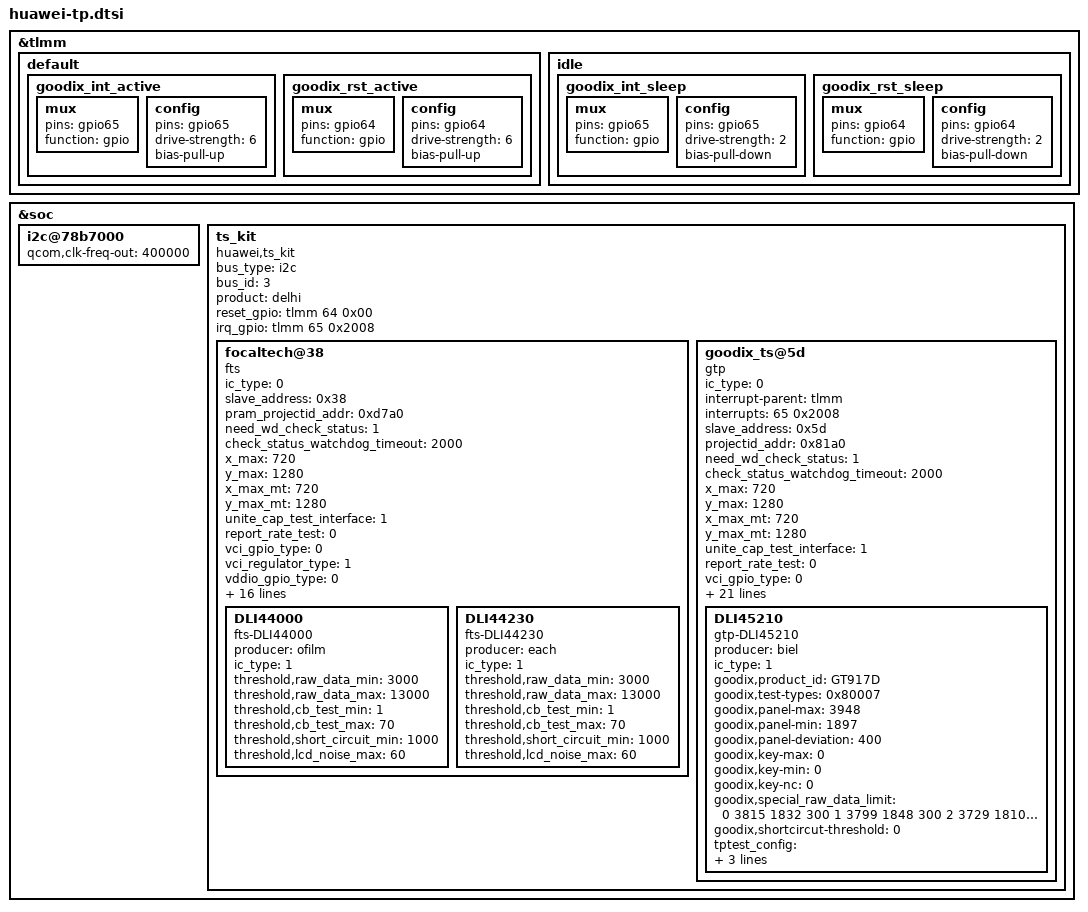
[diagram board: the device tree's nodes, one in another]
/* touch panel config */
&tlmm {

	default {
			goodix_int_active: goodix_int_active{
					mux {
						pins = "gpio65";
						function =  "gpio";
					};
					config {
						pins = "gpio65";
						/*num-grp-pins = <1>;*/
						drive-strength = <6>;
						bias-pull-up;
				};
			};

			goodix_rst_active: goodix_rst_active {
					mux {
						pins = "gpio64";
						function =  "gpio";
					};
					config {
						pins = "gpio64";
						/*num-grp-pins = <1>;*/
						drive-strength = <6>;
						bias-pull-up;
					};
			};
	};

	idle {
			goodix_int_sleep: goodix_int_sleep {
					mux {
						pins = "gpio65";
						function =  "gpio";
					};
					config {
						pins = "gpio65";
						/*num-grp-pins = <1>;*/
						drive-strength = <2>;
						bias-pull-down;
				};
			};

			goodix_rst_sleep: goodix_rst_sleep {
					mux {
						pins = "gpio64";
						function =  "gpio";
					};
					config {
						pins = "gpio64";
						/*num-grp-pins = <1>;*/
						drive-strength = <2>;
						bias-pull-down;
				};
			};
	};

};

&soc {
	i2c@78b7000{
		status = "ok";
		#address-cells = <1>;
		#size-cells = <0>;
		qcom,clk-freq-out = <400000>;
	};
	ts_kit {
		#address-cells = <1>;
		#size-cells = <0>;
		compatible = "huawei,ts_kit";
		bus_type = "i2c";
		bus_id = <3>;
		product = "delhi";
		reset_gpio = <&tlmm 64 0x00>;
		irq_gpio = <&tlmm 65 0x2008>;
		focaltech@38 {
			compatible = "fts";
			ic_type = <0>;
			slave_address = <0x38>;
			pram_projectid_addr = <0xd7a0>;
			need_wd_check_status = <1>;
			check_status_watchdog_timeout = <2000>;
			x_max = <720>;
			y_max = <1280>;
			x_max_mt = <720>;
			y_max_mt = <1280>;
			unite_cap_test_interface =<1>;
			report_rate_test =<0>;
			vci_gpio_type = <0>;
			vci_regulator_type = <1>;
			vddio_gpio_type = <0>;
			vddio_regulator_type = <1>;
			chip_id = <0x54>;
			hard_reset_delay = <200>;
			erase_min_delay = <1350>;
			calc_crc_delay = <300>;
			reboot_delay = <300>;
			erase_query_delay = <50>;
			write_flash_query_times = <30>;
			read_ecc_query_times = <100>;
			erase_flash_query_times = <15>;
			upgrade_loop_times = <5>;
			glove_switch_addr = <0xC0>;
			fts-vdd-supply = <&pm8937_l10>;
			fts-io-supply = <&pm8937_l5>;
			irq_config = <3>;/* 0-low 1-high 2-raising 3-falling */
			algo_id = <1>;
			DLI44000 {
				producer = "ofilm";
				ic_type = <1>;
				compatible = "fts-DLI44000";
				threshold,raw_data_min = <3000>;
				threshold,raw_data_max = <13000>;
				threshold,cb_test_min = <1>;
				threshold,cb_test_max = <70>;
				threshold,short_circuit_min = <1000>;
				//threshold,open_test_cb_min = <100>;
				threshold,lcd_noise_max = <60>;
			};

			DLI44230 {
				producer = "each";
				ic_type = <1>;
				compatible = "fts-DLI44230";
				threshold,raw_data_min = <3000>;
				threshold,raw_data_max = <13000>;
				threshold,cb_test_min = <1>;
				threshold,cb_test_max = <70>;
				threshold,short_circuit_min = <1000>;
				//threshold,open_test_cb_min = <100>;
				threshold,lcd_noise_max = <60>;
			};

		};

		goodix_ts@5d {
			compatible = "gtp";
			ic_type = <0>;
			interrupt-parent = <&tlmm>;
			interrupts = <65 0x2008>;
			slave_address = <0x5d>;
			projectid_addr = <0x81a0>;
			need_wd_check_status = <1>;
			check_status_watchdog_timeout = <2000>;
			x_max = <720>;
			y_max = <1280>;
			x_max_mt = <720>;
			y_max_mt = <1280>;
			unite_cap_test_interface =<1>;
			report_rate_test =<0>;
			vci_gpio_type = <0>;
			vci_regulator_type = <1>;
			vddio_gpio_type = <0>;
			vddio_regulator_type = <1>;
			chip_id = <0x87>;
			hard_reset_delay = <200>;
			erase_min_delay = <1350>;
			calc_crc_delay = <300>;
			reboot_delay = <300>;
			erase_query_delay = <50>;
			write_flash_query_times = <30>;
			read_ecc_query_times = <100>;
			erase_flash_query_times = <15>;
			upgrade_loop_times = <5>;
			glove_switch_addr = <0xC0>;
			pinctrl-names = "default","idle";
			pinctrl-0 = <&goodix_int_active &goodix_rst_active>;
			pinctrl-1 = <&goodix_int_sleep &goodix_rst_sleep>;
			goodix-vdd-supply = <&pm8937_l10>;
			goodix-io-supply = <&pm8937_l5>;
			irq_config = <2>;/* 0-low 1-high 2-raising 3-falling */
			algo_id = <1>;
			DLI45210 {
				producer = "biel";
				ic_type = <1>;
				compatible = "gtp-DLI45210";
				goodix,product_id = "GT917D";
				goodix,test-types = <0x80007>;/*test types*/
				goodix,panel-max = <3948>;
				goodix,panel-min = <1897>;
				goodix,panel-deviation = <400>;
				goodix,key-max = <0>;
				goodix,key-min = <0>;
				goodix,key-nc = <0>;/*key test not check*/
				goodix,special_raw_data_limit = <	0   3815 1832 300 1   3799 1848 300 2   3729 1810 300 3   3658 1773 300 4   3595 1737 300 5   3528 1725 300 6   3467 1684 300 7   3433 1642 300 8   3394 1623 300 9   3346 1617 300 10  3114 1491 300 11  3556 1707 300 12  3590 1702 300 13  3533 1683 300 14  3581 1704 300 15  3556 1695 300 16  3615 1719 300 17  3569 1710 300 18  3573 1698 300 19  3538 1681 300 20  3513 1682 300 21  3283 1580 300
													22  3915 1887 300 23  3905 1905 300 24  3824 1865 300 25  3763 1832 300 26  3691 1796 300 27  3630 1768 300 28  3559 1735 300 29  3532 1696 300 30  3481 1674 300 31  3442 1670 300 32  3209 1564 300 33  3439 1646 300 34  3532 1683 300 35  3491 1665 300 36  3526 1690 300 37  3516 1680 300 38  3558 1698 300 39  3522 1679 300 40  3517 1681 300 41  3494 1668 300 42  3461 1685 300 43  3230 1563 300
													44  3924 1897 300 45  3923 1917 300 46  3847 1875 300 47  3790 1847 300 48  3715 1808 300 49  3663 1784 300 50  3584 1750 300 51  3564 1705 300 52  3508 1688 300 53  3474 1680 300 54  3238 1569 300 55  3421 1626 300 56  3507 1676 300 57  3480 1653 300 58  3496 1679 300 59  3502 1669 300 60  3521 1685 300 61  3504 1659 300 62  3482 1670 300 63  3480 1657 300 64  3430 1660 300 65  3208 1551 300
													66  3927 1901 300 67  3919 1910 300 68  3850 1880 300 69  3784 1840 300 70  3717 1812 300 71  3658 1781 300 72  3591 1754 300 73  3561 1695 300 74  3513 1688 300 75  3467 1673 300 76  3246 1572 300 77  3374 1611 300 78  3476 1655 300 79  3424 1623 300 80  3467 1657 300 81  3446 1635 300 82  3485 1667 300 83  3442 1642 300 84  3439 1647 300 85  3413 1620 300 86  3383 1633 300 87  3156 1511 300
													88  3993 1935 300 89  3989 1953 300 90  3914 1910 300 91  3854 1885 300 92  3784 1842 300 93  3727 1824 300 94  3651 1785 300 95  3628 1738 300 96  3572 1726 300 97  3537 1714 300 98  3298 1601 300 99  3391 1626 300 100 3482 1673 300 101 3447 1642 300 102 3465 1664 300 103 3461 1653 300 104 3487 1679 300 105 3456 1651 300 106 3439 1660 300 107 3431 1634 300 108 3386 1647 300 109 3169 1533 300
													110 3983 1931 300 111 3979 1952 300 112 3905 1915 300 113 3846 1887 300 114 3777 1850 300 115 3721 1827 300 116 3646 1791 300 117 3625 1740 300 118 3568 1725 300 119 3533 1716 300 120 3300 1604 300 121 3352 1614 300 122 3439 1655 300 123 3405 1625 300 124 3424 1647 300 125 3412 1631 300 126 3443 1659 300 127 3408 1642 300 128 3394 1636 300 129 3378 1614 300 130 3382 1627 300 131 3145 1512 300
													132 3880 1908 300 133 3911 1922 300 134 3842 1887 300 135 3773 1871 300 136 3703 1837 300 137 3672 1798 300 138 3604 1760 300 139 3586 1731 300 140 3541 1721 300 141 3506 1700 300 142 3251 1581 300 143 3252 1572 300 144 3333 1628 300 145 3296 1604 300 146 3314 1611 300 147 3307 1609 300 148 3334 1619 300 149 3308 1593 300 150 3286 1595 300 151 3277 1588 300 152 3274 1577 300 153 3065 1471 300
													154 3888 1913 300 155 3918 1929 300 156 3866 1893 300 157 3790 1880 300 158 3723 1839 300 159 3695 1811 300 160 3629 1772 300 161 3603 1742 300 162 3571 1719 300 163 3520 1712 300 164 3268 1597 300 165 3235 1567 300 166 3325 1613 300 167 3281 1599 300 168 3298 1605 300 169 3286 1593 300 170 3309 1605 300 171 3283 1591 300 172 3265 1591 300 173 3253 1580 300 174 3251 1565 300 175 3026 1460 300
													176 3896 1916 300 177 3932 1927 300 178 3873 1895 300 179 3803 1878 300 180 3736 1844 300 181 3721 1819 300 182 3650 1782 300 183 3620 1750 300 184 3577 1730 300 185 3526 1724 300 186 3279 1600 300 187 3229 1547 300 188 3307 1600 300 189 3260 1586 300 190 3283 1585 300 191 3266 1584 300 192 3292 1587 300 193 3257 1573 300 194 3246 1568 300 195 3227 1561 300 196 3217 1549 300 197 2979 1449 300
													198 3915 1918 300 199 3950 1938 300 200 3890 1896 300 201 3827 1888 300 202 3753 1852 300 203 3738 1827 300 204 3665 1792 300 205 3654 1756 300 206 3606 1740 300 207 3558 1735 300 208 3303 1613 300 209 3223 1547 300 210 3294 1594 300 211 3251 1572 300 212 3266 1580 300 213 3252 1571 300 214 3277 1585 300 215 3247 1564 300 216 3227 1565 300 217 3216 1554 300 218 3194 1538 300 219 2983 1441 300
													220 3970 1946 300 221 4011 1971 300 222 3946 1931 300 223 3890 1929 300 224 3829 1890 300 225 3806 1869 300 226 3728 1829 300 227 3714 1801 300 228 3678 1786 300 229 3636 1775 300 230 3377 1651 300 231 3235 1565 300 232 3324 1622 300 233 3272 1602 300 234 3290 1609 300 235 3269 1600 300 236 3303 1601 300 237 3270 1584 300 238 3261 1585 300 239 3238 1574 300 240 3214 1570 300 241 3026 1473 300
													242 3976 1942 300 243 4013 1964 300 244 3951 1929 300 245 3884 1926 300 246 3833 1887 300 247 3802 1872 300 248 3746 1824 300 249 3717 1810 300 250 3681 1787 300 251 3638 1777 300 252 3396 1656 300 253 3195 1551 300 254 3282 1599 300 255 3229 1583 300 256 3247 1586 300 257 3223 1572 300 258 3257 1568 300 259 3223 1568 300 260 3221 1552 300 261 3190 1544 300 262 3174 1548 300 263 2956 1427 300
													264 3886 1891 300 265 3923 1912 300 266 3867 1879 300 267 3807 1878 300 268 3766 1836 300 269 3724 1824 300 270 3668 1778 300 271 3650 1772 300 272 3617 1747 300 273 3582 1740 300 274 3353 1623 300 275 3080 1472 300 276 3165 1522 300 277 3113 1507 300 278 3126 1504 300 279 3110 1497 300 280 3139 1486 300 281 3103 1475 300 282 3087 1467 300 283 3067 1460 300 284 3034 1465 300 285 2830 1353 300
												>;
				goodix,shortcircut-threshold = <0>;
				tptest_config = [
									00 D0 02 00 05 0A 0C 00 01 08
									28 0F 5A 3C 03 05 00 00 00 00
									00 00 04 17 19 1E 14 87 26 BB
									4A 4C 31 0D 00 00 00 21 03 11
									00 00 00 00 00 00 00 00 00 00
									00 00 00 14 00 02 07 00 00 04
									AD 60 00 9D 6B 00 8E 78 00 80
									87 00 75 97 00 75 00 00 00 00
									00 00 00 FF FF 00 00 00 00 00
									00 00 00 00 00 00 00 00 00 00
									00 00 00 00 00 00 00 00 00 00
									00 00 0B 0C 0D 0E 0F 10 11 12
									13 14 15 0A 09 08 07 06 05 04
									03 02 01 00 FF FF FF FF FF FF
									FF FF 28 24 22 20 1F 1E 0A 05
									04 02 00 06 08 FF FF FF FF 00
									00 00 00 00 00 00 00 00 00 00
									00 00 00 00 00 00 00 00 00 00
									00 00 00 00 00 00 00 00 00 00
									00 00 00 00 00 00 00 00 00 00
									00 00 00 00 00 00 00 00 00 00
									00 00 00 00 00 00 00 00 00 00
									00 00 00 00 00 00 D3 01
								];
				normal_config = [
									50 D0 02 00 05 0A 3C 30 01 0F
									28 0F 5A 38 05 F2 00 00 60 62
									12 33 04 16 18 1D 14 C7 26 BB
									39 3B D3 07 7C 06 00 C3 33 91
									00 00 00 00 00 00 C0 0A 0C 00
									1A 28 5B 94 D0 63 08 00 00 04
									92 2B 00 80 33 00 71 3C 00 64
									47 00 5A 54 00 5A 00 00 00 00
									00 00 00 00 00 00 00 22 03 00
									00 00 00 00 17 02 40 00 0F 28
									00 00 00 00 00 06 50 00 00 00
									00 37 0B 0C 0D 0E 0F 10 11 12
									13 14 15 0A 09 08 07 06 05 04
									03 02 01 00 FF FF FF FF FF FF
									FF FF 28 24 22 20 1F 1E 0A 05
									04 02 00 06 08 FF FF FF FF 78
									31 00 00 00 87 70 12 00 28 4E
									5A 14 1E 00 00 3C 08 88 88 00
									82 86 00 3C 00 00 00 00 00 00
									00 00 00 00 00 00 32 00 00 00
									00 00 00 23 50 00 78 78 33 0A
									19 00 00 00 00 00 00 00 00 00
									00 00 00 00 00 00 D2 01
								];
			};
	   };
	};
};

